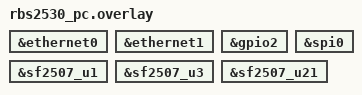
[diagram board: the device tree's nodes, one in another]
&ethernet0 {
	status = "okay";
};

&ethernet1 {
	status = "okay";
};

&gpio2 {
	status = "okay";
};

&spi0 {
	status = "okay";
};

&sf2507_u1 {
	status = "okay";
};

&sf2507_u3 {
	status = "okay";
};

&sf2507_u21 {
	status = "okay";
};
